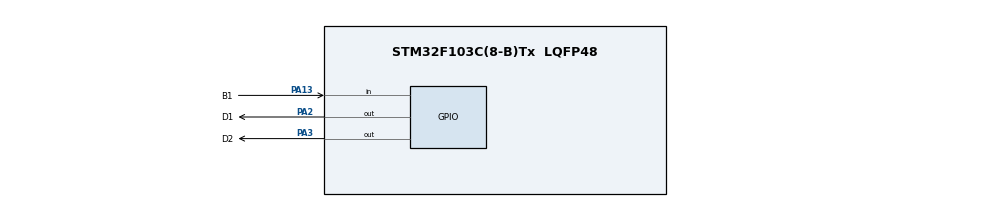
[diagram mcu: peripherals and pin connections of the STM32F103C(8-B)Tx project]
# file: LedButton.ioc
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Mcu.Family=STM32F1
Mcu.Name=STM32F103C(8-B)Tx
Mcu.Package=LQFP48
NVIC.PriorityGroup=NVIC_PRIORITYGROUP_4
PA13.GPIO_Label=B1
PA13.GPIO_PuPd=GPIO_PULLUP
PA13.Signal=GPIO_Input
PA2.GPIO_Label=D1
PA2.Signal=GPIO_Output
PA3.GPIO_Label=D2
PA3.Signal=GPIO_Output
ProjectManager.HeapSize=0x200
ProjectManager.StackSize=0x400
ProjectManager.TargetToolchain=MDK-ARM V5.32
RCC.APB1Freq_Value=8000000
RCC.APB2Freq_Value=8000000
VP_SYS_VS_ND.Mode=No_Debug
board=custom

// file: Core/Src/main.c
/* USER CODE BEGIN Header */
/**
  ******************************************************************************
  * @file           : main.c
  * @brief          : Main program body
  ******************************************************************************
  * @attention
  *
  * Copyright (c) 2025 STMicroelectronics.
  * All rights reserved.
  *
  * This software is licensed under terms that can be found in the LICENSE file
  * in the root directory of this software component.
  * If no LICENSE file comes with this software, it is provided AS-IS.
  *
  ******************************************************************************
  */
/* USER CODE END Header */
#include "main.h"

void SystemClock_Config(void);
static void MX_GPIO_Init(void);

int main(void)
{

  /* MCU Configuration--------------------------------------------------------*/

  /* Reset of all peripherals, Initializes the Flash interface and the Systick. */
  HAL_Init();

  /* Configure the system clock */
  SystemClock_Config();

  /* Initialize all configured peripherals */
  MX_GPIO_Init();

  /* Infinite loop */
  /* USER CODE BEGIN WHILE */
	#define BT_CLICK		GPIO_PIN_RESET
	#define BT_RELEASE	GPIO_PIN_SET
	#define LED_ON			GPIO_PIN_SET
	#define LED_OFF			GPIO_PIN_RESET

	GPIO_PinState	D1_State = LED_OFF;
	HAL_GPIO_WritePin(GPIOA, D1_Pin, D1_State);

	GPIO_PinState	B1_Val;
	uint8_t B1_State = 0;

  while (1)
  {
		B1_Val = HAL_GPIO_ReadPin(GPIOA, B1_Pin);
		if(B1_State == 0) {
			HAL_GPIO_WritePin(GPIOA, D1_Pin, LED_OFF);
			B1_State = 1;
		}
		else if(B1_State == 1) {
			HAL_GPIO_WritePin(GPIOA, D1_Pin, LED_OFF);
			if(B1_Val == BT_CLICK)
				B1_State = 2;
		}
		else if(B1_State == 2) {
			HAL_GPIO_WritePin(GPIOA, D1_Pin, LED_ON);
			if(B1_Val == BT_RELEASE)
				B1_State = 3;
		}

		else if(B1_State == 3) {
			HAL_GPIO_WritePin(GPIOA, D1_Pin, LED_ON);
			if(B1_Val == BT_CLICK) {
				B1_State = 4;
			}
		}
		else if(B1_State == 4) {
				HAL_GPIO_WritePin(GPIOA, D1_Pin, LED_OFF);
				if(B1_Val == BT_RELEASE)
					B1_State = 1;
			}
    /* USER CODE END WHILE */

  }
}

void SystemClock_Config(void)
{
  RCC_OscInitTypeDef RCC_OscInitStruct = {0};
  RCC_ClkInitTypeDef RCC_ClkInitStruct = {0};

  /** Initializes the RCC Oscillators according to the specified parameters
  * in the RCC_OscInitTypeDef structure.
  */
  RCC_OscInitStruct.OscillatorType = RCC_OSCILLATORTYPE_HSI;
  RCC_OscInitStruct.HSIState = RCC_HSI_ON;
  RCC_OscInitStruct.HSICalibrationValue = RCC_HSICALIBRATION_DEFAULT;
  RCC_OscInitStruct.PLL.PLLState = RCC_PLL_NONE;
  if (HAL_RCC_OscConfig(&RCC_OscInitStruct) != HAL_OK)
  {
    Error_Handler();
  }

  /** Initializes the CPU, AHB and APB buses clocks
  */
  RCC_ClkInitStruct.ClockType = RCC_CLOCKTYPE_HCLK|RCC_CLOCKTYPE_SYSCLK
                              |RCC_CLOCKTYPE_PCLK1|RCC_CLOCKTYPE_PCLK2;
  RCC_ClkInitStruct.SYSCLKSource = RCC_SYSCLKSOURCE_HSI;
  RCC_ClkInitStruct.AHBCLKDivider = RCC_SYSCLK_DIV1;
  RCC_ClkInitStruct.APB1CLKDivider = RCC_HCLK_DIV1;
  RCC_ClkInitStruct.APB2CLKDivider = RCC_HCLK_DIV1;

  if (HAL_RCC_ClockConfig(&RCC_ClkInitStruct, FLASH_LATENCY_0) != HAL_OK)
  {
    Error_Handler();
  }
}

static void MX_GPIO_Init(void)
{
  GPIO_InitTypeDef GPIO_InitStruct = {0};

  /* GPIO Ports Clock Enable */
  __HAL_RCC_GPIOA_CLK_ENABLE();

  /*Configure GPIO pin Output Level */
  HAL_GPIO_WritePin(GPIOA, D1_Pin|D2_Pin, GPIO_PIN_RESET);

  /*Configure GPIO pins : D1_Pin D2_Pin */
  GPIO_InitStruct.Pin = D1_Pin|D2_Pin;
  GPIO_InitStruct.Mode = GPIO_MODE_OUTPUT_PP;
  GPIO_InitStruct.Pull = GPIO_NOPULL;
  GPIO_InitStruct.Speed = GPIO_SPEED_FREQ_LOW;
  HAL_GPIO_Init(GPIOA, &GPIO_InitStruct);

  /*Configure GPIO pin : B1_Pin */
  GPIO_InitStruct.Pin = B1_Pin;
  GPIO_InitStruct.Mode = GPIO_MODE_INPUT;
  GPIO_InitStruct.Pull = GPIO_PULLUP;
  HAL_GPIO_Init(B1_GPIO_Port, &GPIO_InitStruct);

}

void Error_Handler(void)
{
  __disable_irq();
  while (1)
  {
  }
}
